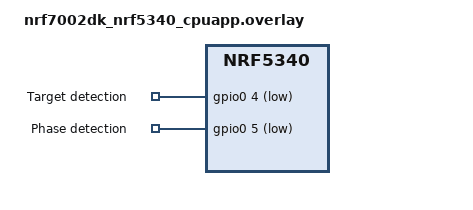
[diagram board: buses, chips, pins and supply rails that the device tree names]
/*
 * Copyright (c) 2021 Nordic Semiconductor ASA
 *
 * SPDX-License-Identifier: LicenseRef-Nordic-5-Clause
 */

#include <zephyr/dt-bindings/ipc_service/static_vrings.h>

/ {
	chosen {
		nordic,pm-ext-flash = &mx25r64;
	};
};

/* Set IPC thread priority to the highest value to not collide with other threads. */
&ipc0 {
    zephyr,priority = <0 PRIO_COOP>;
};

/ {
    bgt60 {
        compatible = "gpio-keys";
        targetd: d_target {
            gpios = <&gpio0 4 GPIO_ACTIVE_LOW>;
            label = "Target detection";
        };
        phased: d_phase {
            gpios = <&gpio0 5 GPIO_ACTIVE_LOW>;
            label = "Phase detection";
        };
    };
    
    aliases {
        targetd = &targetd;
        phased = &phased;
    };
};
